# c71_CPU register map
Vendor: Texas Instruments
Peripheral module from a debugger description file (folder C71).
Registers are 64-bit, access not given, no defined reset value unless marked. A register's access mark holds for its fields unless they carry their own. Offsets are as the file gives them; lines under a group give offsets from that group; [hi:lo] are bit positions; {n}, {i} and the like mark numbered series; 'fields as' and 'values as' point back to an identical list; <NAME> marks a mode.

## CPU — C71-CPU-Registers
0x00 General group — General Registers
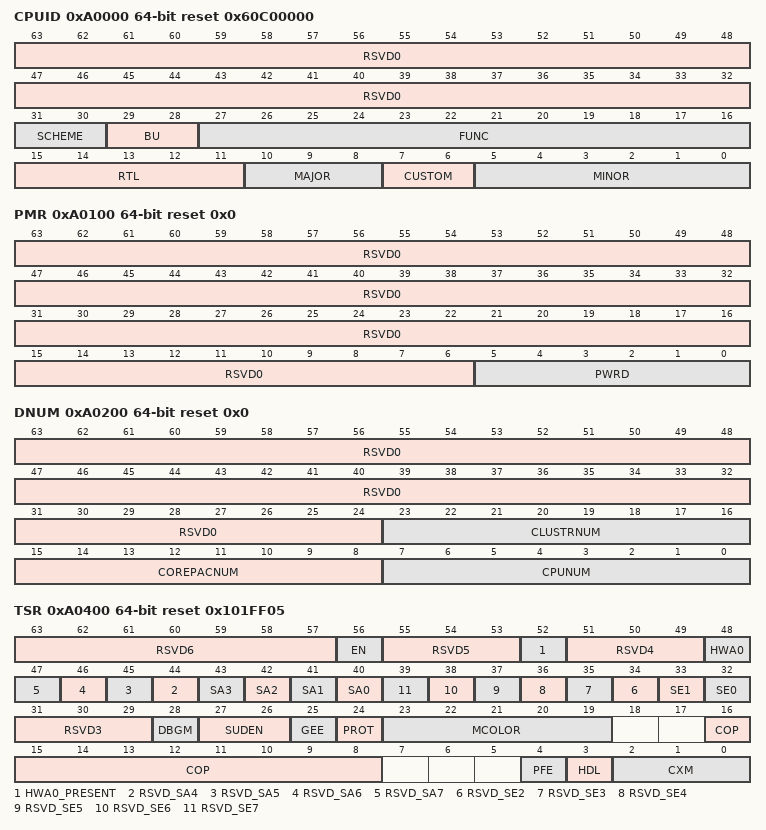
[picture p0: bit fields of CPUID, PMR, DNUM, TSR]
  0xA0000 CPUID ro reset 0x60C00000
    [63:32] RSVD0 — Reserve
    [31:30] SCHEME — Indicates the old scheme vs. new scheme
    [29:28] BU — Business Indicator
    [27:16] FUNC — Function indicates a software compatible module family
    [15:11] RTL — RTL version
    [10:8] MAJOR — Major revision
    [7:6] CUSTOM — Indicates a special version for a particular device
    [5:0] MINOR — Minor revision
  0xA0100 PMR access per field reset 0x0 — Power Management register
    [63:6] RSVD0 ro — Reserve
    [5:0] PWRD rw — Power down mode field
  0xA0200 DNUM ro reset 0x0 — DSP core number register
    [63:24] RSVD0 — Reserve
    [23:16] CLUSTRNUM — Identifies the cluster number of the device
    [15:8] COREPACNUM — Identifies the corepac number within the cluster of the device
    [7:0] CPUNUM — Identifies the DSP core number within the cluster and the corepac of the device
  0xA0300 TSC ro reset 0x0 — Time-stamp counter register
    [63:0] TSC — Time Stamp Counter
  0xA0400 TSR ro reset 0x101FF05 — Task state register
    [63:57] RSVD6 — Reserve
    [56] EN — Endian mode
    [55:53] RSVD5 — Reserve
    [52] HWA0_PRESENT — HWA0 Present at SOC
    [51:49] RSVD4 — Reserve
    [48] HWA0 — HWA0 Active
    [n+40] RSVD_SA{n} (n=4..7) — Streaming Write {n} is active - writable by SAOPEN/SACLOSE only
    [n+40] SA{n} (n=0..3) — Streaming Write {n} is active - writable by SAOPEN/SACLOSE only
    [n+32] RSVD_SE{n} (n=2..7) — Streaming Engine {n} is active - writable by SEOPEN/SECLOSE only
    [33] SE1 — Streaming Engine 1 is active - writable by SEOPEN/SECLOSE only
    [32] SE0 — Streaming Engine 0 is active - writable by SEOPEN/SECLOSE only
    [31:29] RSVD3 — Reserve
    [28] DBGM — Debug access mask. 0: enables debug accesses, 1: disables debug accesses - writable by DDBG and EDBG instructions
    [27:26] SUDEN — Secure User Debug Enable -- writable by instruction RETE only. [26] : invasive debug enable (SUIDEN), [27] : non-invasive debug enable (SUNIDEN). Secure supervisor writable only.
    [25] GEE — Global Event Enable -- Can only be modifed by REVT/DEVT/RETE; Will only disable interrupts destined for own executing level
    [24] PROT — Pipeline Mode - writable by PROT/UNPROT/PROTCLR only
    [23:19] MCOLOR — Memory Tag Color, writable by MTAG instruction only
    [16:8] COP — Current operating priority
    [4] PFE — Speculative Page Fault Enable
    [3] HDL — Current processing mode, 0- Program thread mode; 1-Event handler mode
    [2:0] CXM — Current execution mode, reset value is 0x5
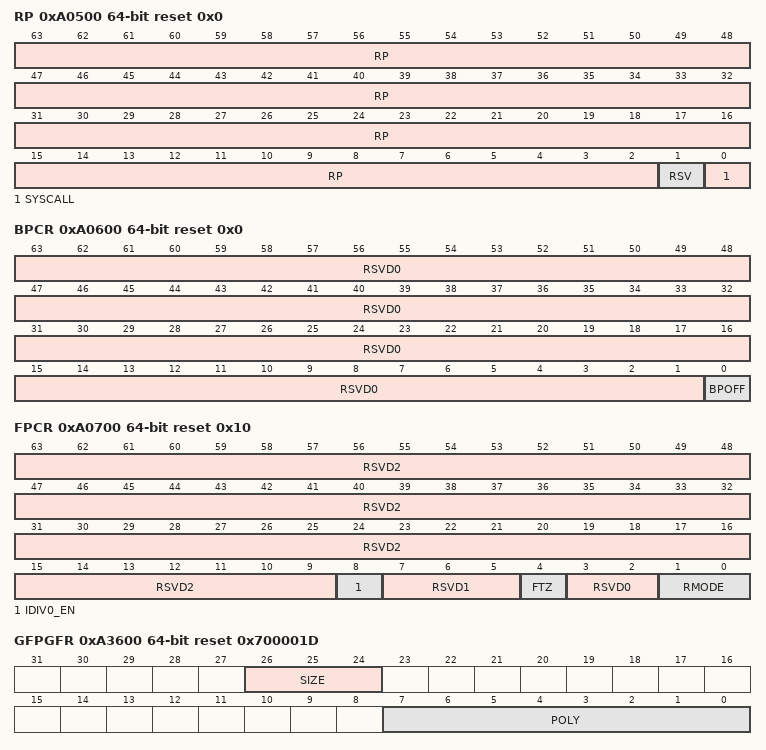
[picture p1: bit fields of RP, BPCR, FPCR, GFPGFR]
  0xA0500 RP access per field reset 0x0 — Return pointer register
    [63:2] RP rw — Return Pointer
    [1] RSV ro — Reserved
    [0] SYSCALL rw — System call: SYSCALL/ROOTCALL/SECCALL executed, 0-Normal Call; 1-System Call
  0xA0600 BPCR access per field reset 0x0 — Branch Predictor Control Register
    [63:1] RSVD0 ro — Reserve
    [0] BPOFF rw — Turn off Branch Predictor if = 1
  0xA3700 GTSC ro reset 0x0 — Global Time Stamp Counter
  0xA3800 STSC ro reset 0x0 — Shadow Time Stamp Counter
  0xA3900 UFCMR rw reset 0x0 — User Flag Clear Mask Register
  0xCFF00 PC rw reset 0x0 — Program counter, E1 phase
    [48:0] PC — Program Counter, read-only in functional mode.
0x00 General Purpose group — General Purpose Registers
  {0x0+0x100*j} A{j} (j=0..15) — Global scalar register {j}
  {0x10000+0x100*j} D{j} (j=0..15) — Local .D1/.D2 register {j}
  {0x20000+0x100*j} AM{j} (j=0..7) — Local .M1 register {j}
  {0x30000+0x100*j} AL{j} (j=0..7) — Local .L1/.S1 register {j}
  {0x60000+0x100*j} BM{j} (j=0..7) — Local .M2/.C register {j}, scalar slice
  {0x70000+0x100*j} BL{j} (j=0..7) — Local .L2/.S2 register {j}, scalar slice
0x00 General Purpose Vector group — General Purpose Vector Registers
  {0x40000+j} VB0[{j}] (j=0..7) — Global vector register 0
  {0x40100+j} VB1[{j}] (j=0..7) — Global vector register 1
  {0x40200+j} VB2[{j}] (j=0..7) — Global vector register 2
  {0x40300+j} VB3[{j}] (j=0..7) — Global vector register 3
  {0x40400+j} VB4[{j}] (j=0..7) — Global vector register 4
  {0x40500+j} VB5[{j}] (j=0..7) — Global vector register 5
  {0x40600+j} VB6[{j}] (j=0..7) — Global vector register 6
  {0x40700+j} VB7[{j}] (j=0..7) — Global vector register 7
  {0x40800+j} VB8[{j}] (j=0..7) — Global vector register 8
  {0x40900+j} VB9[{j}] (j=0..7) — Global vector register 9
  {0x40A00+j} VB10[{j}] (j=0..7) — Global vector register 10
  {0x40B00+j} VB11[{j}] (j=0..7) — Global vector register 11
  {0x40C00+j} VB12[{j}] (j=0..7) — Global vector register 12
  {0x40D00+j} VB13[{j}] (j=0..7) — Global vector register 13
  {0x40E00+j} VB14[{j}] (j=0..7) — Global vector register 14
  {0x40F00+j} VB15[{j}] (j=0..7) — Global vector register 15
  {0x50000+0x100*j} P{j} (j=0..7) — Vector Predicate register {j}
  {0x60000+j} VBM0[{j}] (j=0..7) — Local .M2/.C register 0
  {0x60100+j} VBM1[{j}] (j=0..7) — Local .M2/.C register 1
  {0x60200+j} VBM2[{j}] (j=0..7) — Local .M2/.C register 2
  {0x60300+j} VBM3[{j}] (j=0..7) — Local .M2/.C register 3
  {0x60400+j} VBM4[{j}] (j=0..7) — Local .M2/.C register 4
  {0x60500+j} VBM5[{j}] (j=0..7) — Local .M2/.C register 5
  {0x60600+j} VBM6[{j}] (j=0..7) — Local .M2/.C register 6
  {0x60700+j} VBM7[{j}] (j=0..7) — Local .M2/.C register 7
  {0x70000+j} VBL0[{j}] (j=0..7) — Local .L2/.S2 register 0
  {0x70100+j} VBL1[{j}] (j=0..7) — Local .L2/.S2 register 1
  {0x70200+j} VBL2[{j}] (j=0..7) — Local .L2/.S2 register 2
  {0x70300+j} VBL3[{j}] (j=0..7) — Local .L2/.S2 register 3
  {0x70400+j} VBL4[{j}] (j=0..7) — Local .L2/.S2 register 4
  {0x70500+j} VBL5[{j}] (j=0..7) — Local .L2/.S2 register 5
  {0x70600+j} VBL6[{j}] (j=0..7) — Local .L2/.S2 register 6
  {0x70700+j} VBL7[{j}] (j=0..7) — Local .L2/.S2 register 7
0x00 Computation group — Computation Registers
  0xA0700 FPCR access per field reset 0x10 — Floating-point control register
    [63:9] RSVD2 ro — Reserve
    [8] IDIV0_EN rw — Integer Divide by 0 Exception Enable
    [7:5] RSVD1 ro — Reserve
    [4] FTZ rw — Flush-to-zero mode
    [3:2] RSVD0 ro — Reserve
    [1:0] RMODE rw — Floating Point Rounding Mode
  0xA0800 FSR rw reset 0x0 — Flag status register
    [8n+7] SAT_{n} (n=0..7) — Result is saturated Fixed Point Flag, vector_slice{n}
    [8n+6] UNORD_{n} (n=0..7) — Compare result is unordered Floating Point Flag, vector_slice{n}
    [8n+5] DEN_{n} (n=0..7) — Source is a Denorm Floating Point Flag, vector_slice{n}
    [8n+4] INEX_{n} (n=0..7) — Result is inexact Floating Point Flag, vector_slice{n}
    [8n+3] UNDER_{n} (n=0..7) — Result is underflow Floating Point Flag, vector_slice{n}
    [8n+2] OVER_{n} (n=0..7) — Result is overflow Floating Point Flag, vector_slice{n}
    [8n+1] DIV0_{n} (n=0..7) — Divide by zero Floating Point Flag, vector_slice{n}
    [8n] INVAL_{n} (n=0..7) — Invalid Operations Floating Point Flag, scalar slice || vector_slice{n}
  0xA3500 GPLY access per field reset 0x0 — Galois Polynomial Register
    [31:0] GPLY rw
  0xA3600 GFPGFR access per field reset 0x700001D — Galois Field Polynomial Generator Function Register
    [26:24] SIZE rw
    [7:0] POLY rw — Polynomial Generator
  {0xB0000+j} CUCR0[{j}] (j=0..7) — .C unit Control Register 0
  {0xB0100+j} CUCR1[{j}] (j=0..7) — .C unit Control Register 1
  {0xB0200+j} CUCR2[{j}] (j=0..7) — .C unit Control Register 2
  {0xB0300+j} CUCR3[{j}] (j=0..7) — .C unit Control Register 3
0x00 Exception group — Exception Registers
  0xA0900 ECLMR rw reset 0xFFFFFFFFFFFFFFFF — Event Claim Register
    [63:0] ECLMR — Claimed interrupts Register, Secure Supervisor claim only
  0xA0A00 EASGR rw reset 0x0 — Event Assign Register
    [63:0] EASGR — Event Assign Register, Root Supervisor, SS and S can assign
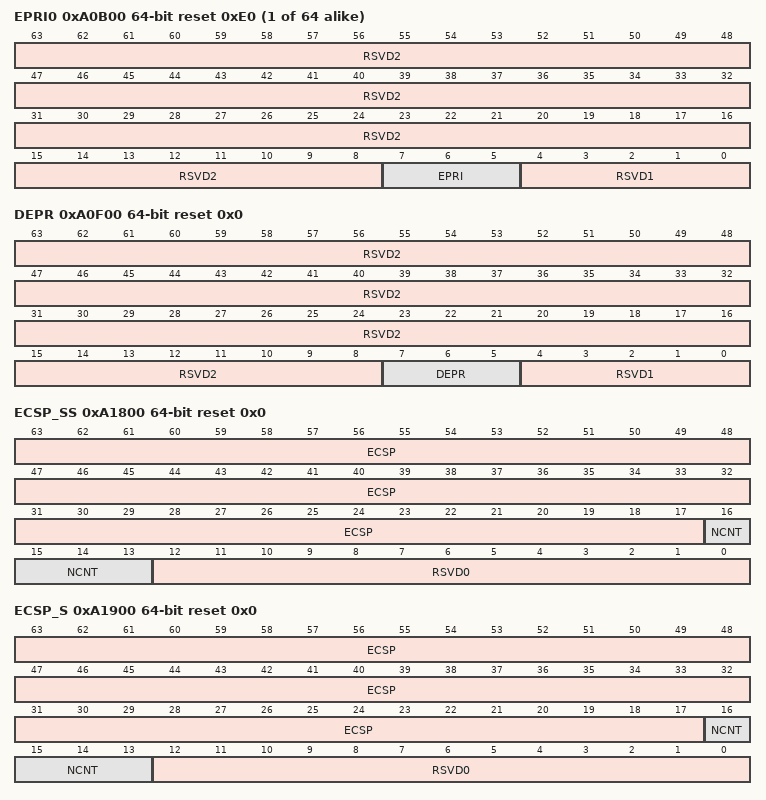
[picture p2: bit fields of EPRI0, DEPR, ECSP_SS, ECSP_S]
  {0xA0B00+0x100000*j} EPRI{j} access per field reset 0xE0 (j=0..63) — Event Priority Register Event priority Register Index {j}
    [63:8] RSVD2 ro — Reserve
    [7:5] EPRI rw — Event Priority Number
    [4:0] RSVD1 ro — Reserve
  0xA0C00 EER ro reset 0x0 — Event Enable Register
    [63:0] EER — Event Flag register
  0xA0D00 EESET — Event Enable Set Register
  0xA0E00 EECLR — Event Enable Clear Register
  0xA0F00 DEPR access per field reset 0x0 — Debug Event Priority Register
    [63:8] RSVD2 ro — Reserve
    [7:5] DEPR rw — Debug Event Priority Number
    [4:0] RSVD1 ro — Reserve
  0xA1000 EFR ro reset 0x0 — Event Flag Register
    [63:0] EFR — Event Flag register
  0xA1100 EFSET — Event Flag Set Register
  0xA1200 EFCLR — Event Flag Clear Register
  0xA1300 IESET rw reset 0x0 — Internal Exception Event Set Register
    [63:0] IESET — Internal Event Set Register
  0xA1400 ESTP_SS rw reset 0x0 — Event Service Table Pointer Register, Secure Supervisor
    [63:0] ESTB — Interrupt Service Table Pointer
  0xA1500 ESTP_S rw reset 0x0 — Event Service Table Pointer Register, Supervisor
    [63:0] ESTB — Interrupt Service Table Pointer
  0xA1600 ESTP_GS rw reset 0x0 — Event Service Table Pointer Register, Guest Supervisor
    [63:0] ESTB — Interrupt Service Table Pointer
  0xA1700 EDR ro reset 0x0 — Event Dropped Register
    [63:0] EDR — Dropped Event Register
  0xA1800 ECSP_SS access per field reset 0x0 — Event Context Save Pointer, Secure Supervisor
    [63:17] ECSP rw — Event Context Save Pointer
    [16:13] NCNT rw — Event Context NCNT
    [12:0] RSVD0 ro — Reserve
  0xA1900 ECSP_S access per field reset 0x0 — Event Context Save Pointer, Supervisor
    fields as Exception.ECSP_SS
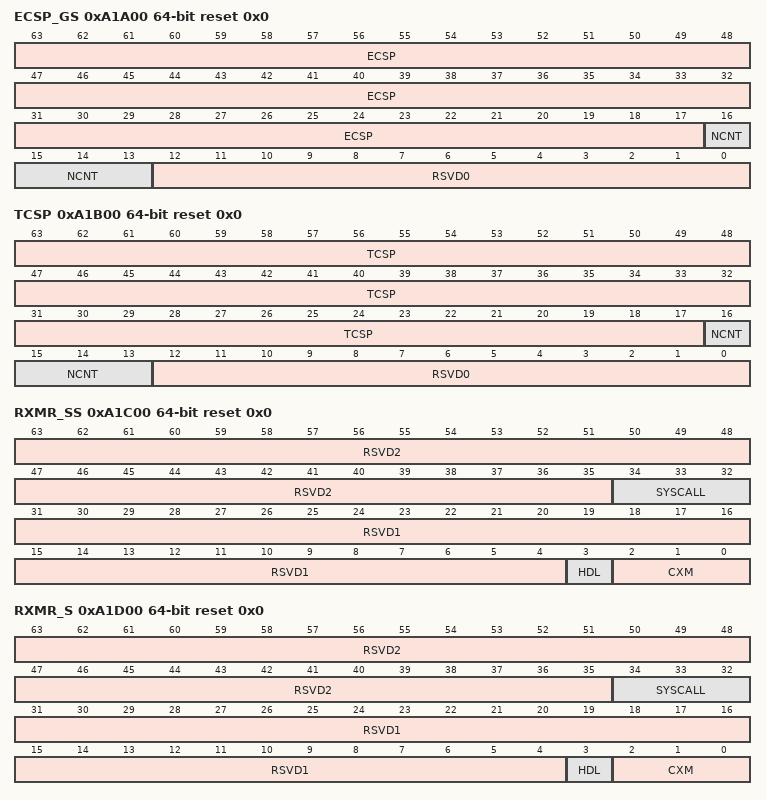
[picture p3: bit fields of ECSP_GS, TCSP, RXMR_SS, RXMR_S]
  0xA1A00 ECSP_GS access per field reset 0x0 — Event Context Save Pointer, Guest Supervisor
    fields as Exception.ECSP_SS
  0xA1B00 TCSP access per field reset 0x0 — Task Context Save Pointer
    [63:17] TCSP rw — User Context Save Pointer
    [16:13] NCNT rw — Event Context NCNT
    [12:0] RSVD0 ro — Reserve
  0xA1C00 RXMR_SS access per field reset 0x0 — Returning Execution Mode Register, Secure Supervisor
    [63:35] RSVD2 ro — Reserve
    [34:32] SYSCALL rw — Returning execution mode from System Call when RETS is executed
    [31:4] RSVD1 ro — Reserve
    [3] HDL rw — Returning handler bit
    [2:0] CXM rw — Returning execution mode
  0xA1D00 RXMR_S access per field reset 0x0 — Returning Execution Mode Register, Supervisor
    fields as Exception.RXMR_SS
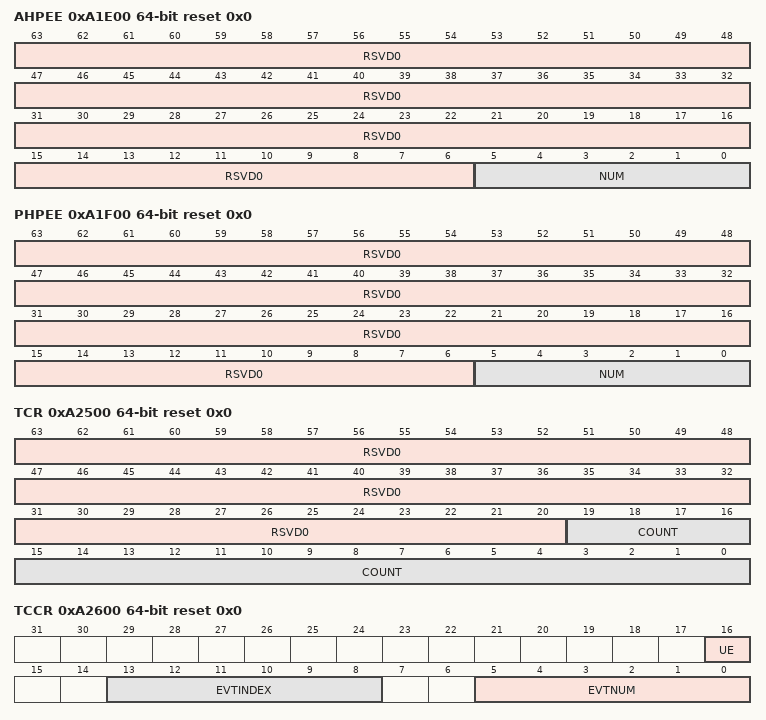
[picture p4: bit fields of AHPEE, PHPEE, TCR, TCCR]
  0xA1E00 AHPEE ro reset 0x0 — Highest Priority Enabled Event, Currently in service
    [63:6] RSVD0 — Reserve
    [5:0] NUM — Highest Priority Enabled Event
  0xA1F00 PHPEE ro reset 0x0 — Pending HPEE
    [63:6] RSVD0 — Reserve
    [5:0] NUM — Highest Priority Enabled Event
  0xA2000 IPE — Inter-processor Events Register
  0xA2100 IERR rw reset 0x0 — Internal exception report register
  0xA2200 IEAR rw reset 0x0 — Internal Exception Address Register
    [63:0] IEAR — Internal Event Address Register
  0xA2300 IESR rw reset 0x0 — Internal exception Status Register
    [63:0] IESR — Internal Event Status Register
  0xA2400 IEDR rw reset 0x0 — Internal Exception Data Register
    [63:0] IEDR — Reserved
  0xA2500 TCR access per field reset 0x0 — Test Count register
    [63:20] RSVD0 ro — Test Counter Register Count Value
    [19:0] COUNT rw — Test Counter Register
  0xA2600 TCCR access per field reset 0x0 — Test Count Config register
    [16] UE rw — User mode enable bit
    [13:8] EVTINDEX rw — Event number index group for count-to-zero event triggered
    [5:0] EVTNUM rw — Event number for count-to-zero event triggered
  0xA2700 GMER access per field reset 0x0 — Guest Mode Enable Register
    [0] SECCALLEN rw — SECCALL enable 0: GS cannot make SECCALL; 1: GS can make SECCALL
  0xA2800 UMER access per field reset 0x0 — User Mask Enable Register
    [0] UMEN rw
  0xA2900 SPBR rw reset 0x0 — Stack pointer boundary Register
    [63:0] SPBR — Stack Pointer Boundary
0x00 LUT group — LUT Registers
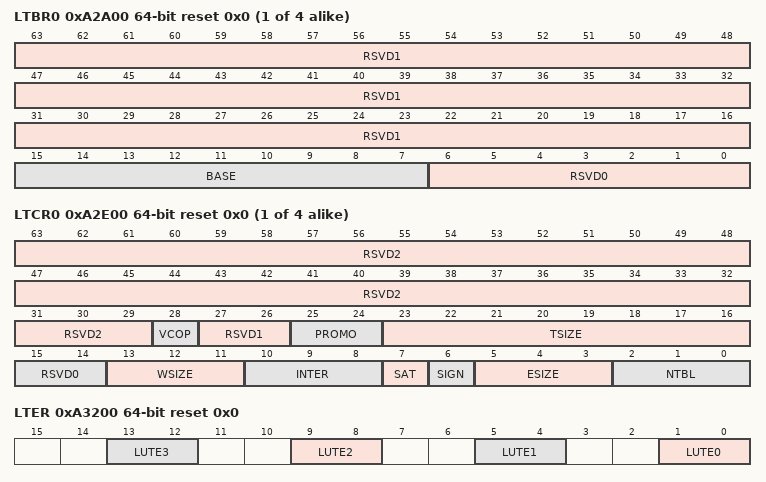
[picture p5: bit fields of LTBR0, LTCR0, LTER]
  {0xA2A00+0x100*j} LTBR{j} access per field reset 0x0 (j=0..3) — Lookup Table Base Address register {j}
    [63:16] RSVD1 ro — Reserve
    [15:7] BASE rw — Base Address
    [6:0] RSVD0 ro — Reserve
  {0xA2E00+0x100*j} LTCR{j} access per field reset 0x0 (j=0..3) — Lookup Table configuration register {j}
    [63:29] RSVD2 ro — Reserve
    [28] VCOP rw — VCOP bit to tell L1D to interpret memory configuration: 0: native c7x, 1: same as EVE
    [27:26] RSVD1 ro — Reserve
    [25:24] PROMO rw — Levels of precision promotion: 2b'00 -- No Promote 2b'01 -- Promote_2X -> B->H, H->W, W->D 2b'10 -- Promote_4X -> B->W, H->D 2b'11 -- Promote_8X -> Promote B->D
    [23:16] TSIZE rw — Table size
    [15:14] RSVD0 ro — Reserve
    [13:11] WSIZE rw — Histogram Weight Sizes
    [10:8] INTER rw — Interpolating
    [7] SAT rw — 1: Result is saturated, 0: Result is not saturated
    [6] SIGN rw — 1: Signed, 0: Unsigned
    [5:3] ESIZE rw — Element size
    [2:0] NTBL rw — Number of tables
  0xA3200 LTER access per field reset 0x0 — Lookup Table Enable register
    [4n+1:4n] LUTE{n} rw (n=0..3) — Enable look up table set {n}
0x00 Streaming Address group — Streaming Address Registers
  {0xB0400+j} SA0CR[{j}] (j=0..7) — Streaming address generator configuration register 0[Access Permissions: Guest User=RW, Guest Supervisor=RW, User=RW, Supervisor=RW, Secure User=RW, Secure Supervisor=RW]
  {0xB0500+j} SA0CNTR0[{j}] (j=0..7) — Streaming address generator counter register 0[Access Permissions: Guest User=RW, Guest Supervisor=RW, User=RW, Supervisor=RW, Secure User=RW, Secure Supervisor=RW]
  {0xB0600+j} SA1CR[{j}] (j=0..7) — Streaming address generator configuration register 1[Access Permissions: Guest User=RW, Guest Supervisor=RW, User=RW, Supervisor=RW, Secure User=RW, Secure Supervisor=RW]
  {0xB0700+j} SA0CNTR1[{j}] (j=0..7) — Streaming address generator counter register 1[Access Permissions: Guest User=RW, Guest Supervisor=RW, User=RW, Supervisor=RW, Secure User=RW, Secure Supervisor=RW]
  {0xB0800+j} SA2CR[{j}] (j=0..7) — Streaming address generator configuration register 2[Access Permissions: Guest User=RW, Guest Supervisor=RW, User=RW, Supervisor=RW, Secure User=RW, Secure Supervisor=RW]
  {0xB0900+j} SA0CNTR2[{j}] (j=0..7) — Streaming address generator counter register 2[Access Permissions: Guest User=RW, Guest Supervisor=RW, User=RW, Supervisor=RW, Secure User=RW, Secure Supervisor=RW]
  {0xB0A00+j} SA3CR[{j}] (j=0..7) — Streaming address generator configuration register 3[Access Permissions: Guest User=RW, Guest Supervisor=RW, User=RW, Supervisor=RW, Secure User=RW, Secure Supervisor=RW]
  {0xB0B00+j} SA0CNTR3[{j}] (j=0..7) — Streaming address generator counter register 3[Access Permissions: Guest User=RW, Guest Supervisor=RW, User=RW, Supervisor=RW, Secure User=RW, Secure Supervisor=RW]
  {0xB0C00+0x100*j} SA{j} ro reset 0x0 (j=0..3) — Streaming Address Offset Register {j}
    [31:0] SA_OFFSET — SA offset value
  {0xD0000+j} PSA{j} ro reset 0x0 (j=0..3) — Streaming Address Predicate Register {j}
    [63:0] PSA — SA byte enables
0x00 Debug group — Registers useful for debug
  0x10F00 SP — Stack Pointer (D15)
  0x10F00 FP — Frame Pointer (D15)
  0xA3300 DBGCTXT access per field reset 0x0 — Debug Context (Overlay) Register
    [31:0] DBGCTXT rw — Debug Context Switch Register
  0xA3400 PC_PROF rw reset 0x0
    [63:0] PC_PROF — PC Profile Register
  0xCF000 ILCNT ro reset 0x0 — Inner Loop Counter Register
    [63:0] ILCNT — Inner Loop Count
  0xCF100 ILCNT_INIT ro reset 0x0 — Inner Loop Counter Initial Value Register
    [63:0] ILCNT_INIT — Inner Loop Count Initial Value
  0xCF200 OLCNT ro reset 0x0 — Inner Loop Counter Initial Value Register
    [63:0] OLCNT — Outer Loop Count
  0xCF300 EPISKEW ro reset 0x0 — Set number of additional taken branches to take, k=-1,..30, k is called EPISKEW
    [5:0] EPISKEW
  0xCF400 LCNTFLAG ro reset 0x0 — 16-bit predicate flags
    [63:0] FLG — Loop Counter Flags
  {0xCF500+j} SCRB[{j}] (j=0..7) — Scoreboard Bits Register -- For Debug only
  {0xCFA00+j} SE0[{j}] (j=0..7) — Streaming Engine Data Register 0 -- For Debug only[Access Permissions: Non-Secure Debug=R, Secure Debug=R]
  {0xCFB00+j} SE1[{j}] (j=0..7) — Streaming Engine Data Register 1 -- For Debug only[Access Permissions: Non-Secure Debug=R, Secure Debug=R]
  0xCFF00 PC rw reset 0x0 — Program counter, E1 phase
    [48:0] PC — Program Counter, read-only in functional mode.
